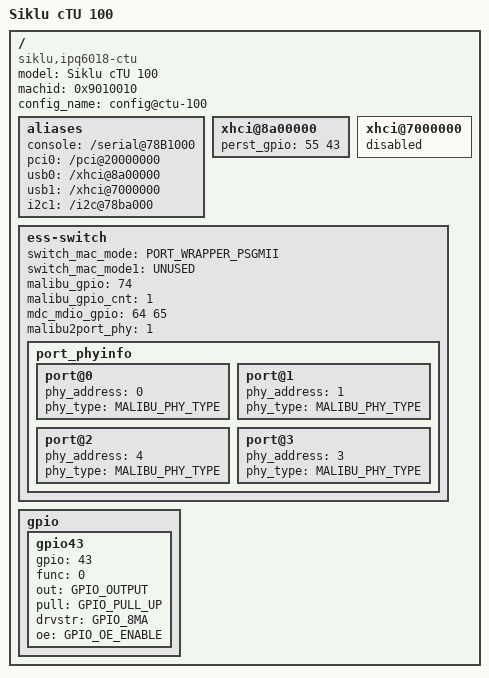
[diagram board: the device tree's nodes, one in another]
/*
 * Copyright (c) 2019, The Linux Foundation. All rights reserved.
 *
 * This program is free software; you can redistribute it and/or modify
 * it under the terms of the GNU General Public License version 2 and
 * only version 2 as published by the Free Software Foundation.
 *
 * This program is distributed in the hope that it will be useful,
 * but WITHOUT ANY WARRANTY; without even the implied warranty of
 * MERCHANTABILITY or FITNESS FOR A PARTICULAR PURPOSE.  See the
 * GNU General Public License for more details.
 */

/dts-v1/;
#include "ipq6018-soc.dtsi"
/ {
	model = "Siklu cTU 100";
	compatible = "siklu,ipq6018-ctu", "qcom,ipq6018";
	machid = <0x9010010>;
	config_name = "config@ctu-100";

	aliases {
		console = "/serial@78B1000";
		pci0 = "/pci@20000000";
		usb0 = "/xhci@8a00000";
		usb1 = "/xhci@7000000";
		i2c1 = "/i2c@78ba000";
	};

	xhci@8a00000 {
		perst_gpio = <55 43>;
	};

	xhci@7000000 {
		status = "disabled";
	};

	ess-switch {
		switch_mac_mode = <PORT_WRAPPER_PSGMII>;
		switch_mac_mode1 = <UNUSED>;
		malibu_gpio = <74>;
		malibu_gpio_cnt = <1>;
		mdc_mdio_gpio = <64 65>;
		malibu2port_phy = <1>;
		port_phyinfo {
			port@0 {
				phy_address = <0>;
				phy_type = <MALIBU_PHY_TYPE>;
			};
			port@1 {
				phy_address = <1>;
				phy_type = <MALIBU_PHY_TYPE>;
			};
			port@2 {
				phy_address = <4>;
				phy_type = <MALIBU_PHY_TYPE>;
			};
			port@3 {
				phy_address = <3>;
				phy_type = <MALIBU_PHY_TYPE>;
			};
		};
	};

	gpio {
		gpio43 {
			gpio = <43>;
			func = <0>;
			out  = <GPIO_OUTPUT>;
			pull = <GPIO_PULL_UP>;
			drvstr = <GPIO_8MA>;
			oe = <GPIO_OE_ENABLE>;
		};
	};
};

